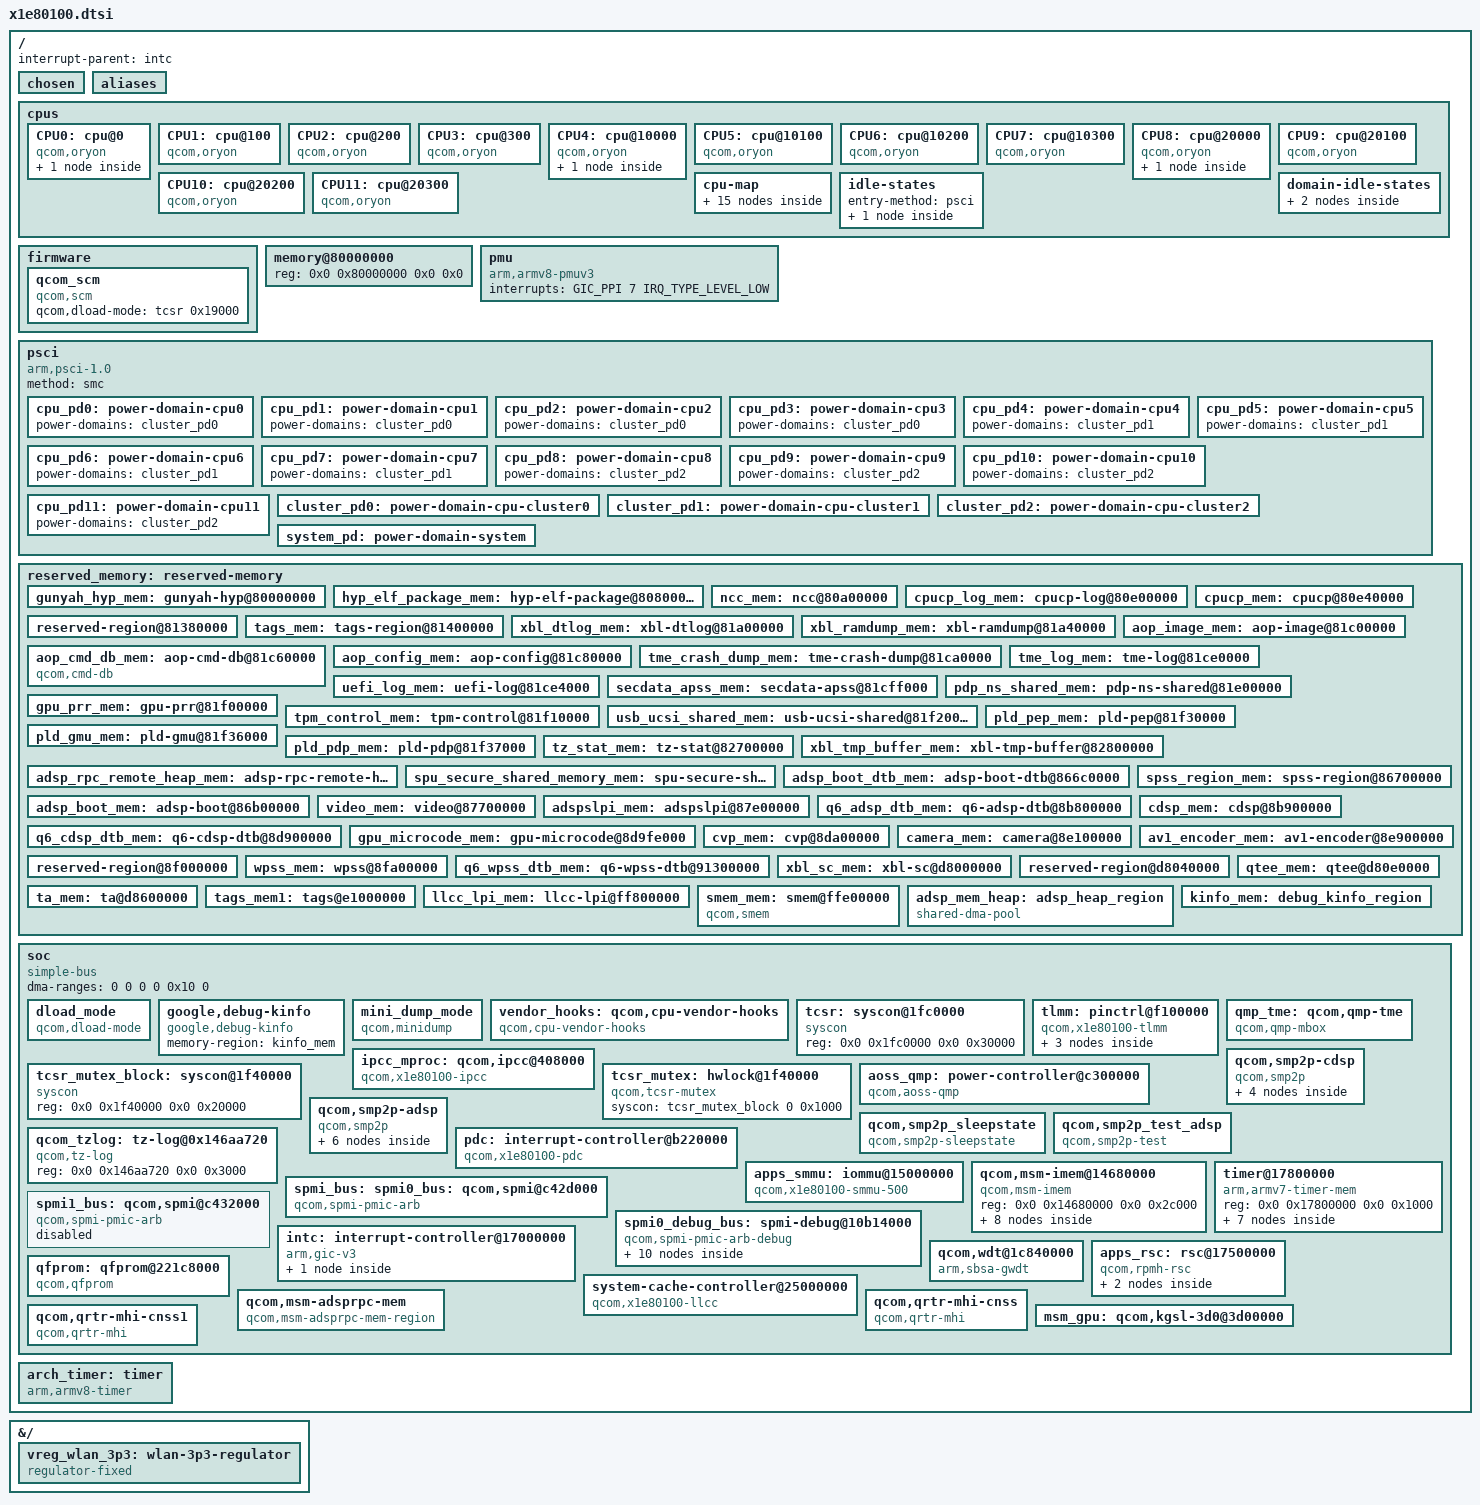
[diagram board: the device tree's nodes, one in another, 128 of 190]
// SPDX-License-Identifier: BSD-3-Clause
/*
 * Copyright (c) Qualcomm Technologies, Inc. and/or its subsidiaries.
 */

#include <dt-bindings/gpio/gpio.h>
#include <dt-bindings/interrupt-controller/arm-gic.h>
#include <dt-bindings/mailbox/qcom-ipcc.h>
#include <dt-bindings/soc/qcom,rpmh-rsc.h>
#include <dt-bindings/spmi/spmi.h>

/ {
	interrupt-parent = <&intc>;

	#address-cells = <2>;
	#size-cells = <2>;

	chosen { };

	aliases { };

	cpus {
		#address-cells = <2>;
		#size-cells = <0>;

		CPU0: cpu@0 {
			device_type = "cpu";
			compatible = "qcom,oryon";
			reg = <0x0 0x0>;
			enable-method = "psci";
			next-level-cache = <&L2_0>;
			power-domains = <&cpu_pd0>;
			power-domain-names = "psci";
			cpu-idle-states = <&cluster_c4>;

			L2_0: l2-cache {
				compatible = "cache";
				cache-level = <2>;
				cache-unified;
			};
		};

		CPU1: cpu@100 {
			device_type = "cpu";
			compatible = "qcom,oryon";
			reg = <0x0 0x100>;
			enable-method = "psci";
			next-level-cache = <&L2_0>;
			power-domains = <&cpu_pd1>;
			power-domain-names = "psci";
			cpu-idle-states = <&cluster_c4>;
		};

		CPU2: cpu@200 {
			device_type = "cpu";
			compatible = "qcom,oryon";
			reg = <0x0 0x200>;
			enable-method = "psci";
			next-level-cache = <&L2_0>;
			power-domains = <&cpu_pd2>;
			power-domain-names = "psci";
			cpu-idle-states = <&cluster_c4>;
		};

		CPU3: cpu@300 {
			device_type = "cpu";
			compatible = "qcom,oryon";
			reg = <0x0 0x300>;
			enable-method = "psci";
			next-level-cache = <&L2_0>;
			power-domains = <&cpu_pd3>;
			power-domain-names = "psci";
			cpu-idle-states = <&cluster_c4>;
		};

		CPU4: cpu@10000 {
			device_type = "cpu";
			compatible = "qcom,oryon";
			reg = <0x0 0x10000>;
			enable-method = "psci";
			next-level-cache = <&L2_1>;
			power-domains = <&cpu_pd4>;
			power-domain-names = "psci";
			cpu-idle-states = <&cluster_c4>;

			L2_1: l2-cache {
				compatible = "cache";
				cache-level = <2>;
				cache-unified;
			};
		};

		CPU5: cpu@10100 {
			device_type = "cpu";
			compatible = "qcom,oryon";
			reg = <0x0 0x10100>;
			enable-method = "psci";
			next-level-cache = <&L2_1>;
			power-domains = <&cpu_pd5>;
			power-domain-names = "psci";
			cpu-idle-states = <&cluster_c4>;
		};

		CPU6: cpu@10200 {
			device_type = "cpu";
			compatible = "qcom,oryon";
			reg = <0x0 0x10200>;
			enable-method = "psci";
			next-level-cache = <&L2_1>;
			power-domains = <&cpu_pd6>;
			power-domain-names = "psci";
			cpu-idle-states = <&cluster_c4>;
		};

		CPU7: cpu@10300 {
			device_type = "cpu";
			compatible = "qcom,oryon";
			reg = <0x0 0x10300>;
			enable-method = "psci";
			next-level-cache = <&L2_1>;
			power-domains = <&cpu_pd7>;
			power-domain-names = "psci";
			cpu-idle-states = <&cluster_c4>;
		};

		CPU8: cpu@20000 {
			device_type = "cpu";
			compatible = "qcom,oryon";
			reg = <0x0 0x20000>;
			enable-method = "psci";
			next-level-cache = <&L2_2>;
			power-domains = <&cpu_pd8>;
			power-domain-names = "psci";
			cpu-idle-states = <&cluster_c4>;

			L2_2: l2-cache {
				compatible = "cache";
				cache-level = <2>;
				cache-unified;
			};
		};

		CPU9: cpu@20100 {
			device_type = "cpu";
			compatible = "qcom,oryon";
			reg = <0x0 0x20100>;
			enable-method = "psci";
			next-level-cache = <&L2_2>;
			power-domains = <&cpu_pd9>;
			power-domain-names = "psci";
			cpu-idle-states = <&cluster_c4>;
		};

		CPU10: cpu@20200 {
			device_type = "cpu";
			compatible = "qcom,oryon";
			reg = <0x0 0x20200>;
			enable-method = "psci";
			next-level-cache = <&L2_2>;
			power-domains = <&cpu_pd10>;
			power-domain-names = "psci";
			cpu-idle-states = <&cluster_c4>;
		};

		CPU11: cpu@20300 {
			device_type = "cpu";
			compatible = "qcom,oryon";
			reg = <0x0 0x20300>;
			enable-method = "psci";
			next-level-cache = <&L2_2>;
			power-domains = <&cpu_pd11>;
			power-domain-names = "psci";
			cpu-idle-states = <&cluster_c4>;
		};

		cpu-map {
			cluster0 {
				core0 {
					cpu = <&CPU0>;
				};

				core1 {
					cpu = <&CPU1>;
				};

				core2 {
					cpu = <&CPU2>;
				};

				core3 {
					cpu = <&CPU3>;
				};
			};

			cluster1 {
				core0 {
					cpu = <&CPU4>;
				};

				core1 {
					cpu = <&CPU5>;
				};

				core2 {
					cpu = <&CPU6>;
				};

				core3 {
					cpu = <&CPU7>;
				};
			};

			cpu_map_cluster2: cluster2 {
				core0 {
					cpu = <&cpu8>;
				};

				core1 {
					cpu = <&cpu9>;
				};

				core2 {
					cpu = <&cpu10>;
				};

				core3 {
					cpu = <&cpu11>;
				};

			};
		};

		idle-states {
			entry-method = "psci";

			cluster_c4: cpu-sleep-0 {
				compatible = "arm,idle-state";
				idle-state-name = "ret";
				arm,psci-suspend-param = <0x00000004>;
				entry-latency-us = <180>;
				exit-latency-us = <500>;
				min-residency-us = <600>;
			};
		};

		domain-idle-states {
			cluster_cl4: cluster-sleep-0 {
				compatible = "domain-idle-state";
				arm,psci-suspend-param = <0x01000044>;
				entry-latency-us = <350>;
				exit-latency-us = <500>;
				min-residency-us = <2500>;
			};

			cluster_cl5: cluster-sleep-1 {
				compatible = "domain-idle-state";
				arm,psci-suspend-param = <0x01000054>;
				entry-latency-us = <2200>;
				exit-latency-us = <4000>;
				min-residency-us = <7000>;
			};
		};
	};

	firmware {
		qcom_scm {
			compatible = "qcom,scm";
			qcom,dload-mode = <&tcsr 0x19000>;
		};
	};

	memory@80000000 {
		device_type = "memory";
		/* We expect the bootloader to fill in the size */
		reg = <0x0 0x80000000 0x0 0x0>;
	};

	pmu {
		compatible = "arm,armv8-pmuv3";
		interrupts = <GIC_PPI 7 IRQ_TYPE_LEVEL_LOW>;
	};

	psci {
		compatible = "arm,psci-1.0";
		method = "smc";

		cpu_pd0: power-domain-cpu0 {
			#power-domain-cells = <0>;
			power-domains = <&cluster_pd0>;
		};

		cpu_pd1: power-domain-cpu1 {
			#power-domain-cells = <0>;
			power-domains = <&cluster_pd0>;
		};

		cpu_pd2: power-domain-cpu2 {
			#power-domain-cells = <0>;
			power-domains = <&cluster_pd0>;
		};

		cpu_pd3: power-domain-cpu3 {
			#power-domain-cells = <0>;
			power-domains = <&cluster_pd0>;
		};

		cpu_pd4: power-domain-cpu4 {
			#power-domain-cells = <0>;
			power-domains = <&cluster_pd1>;
		};

		cpu_pd5: power-domain-cpu5 {
			#power-domain-cells = <0>;
			power-domains = <&cluster_pd1>;
		};

		cpu_pd6: power-domain-cpu6 {
			#power-domain-cells = <0>;
			power-domains = <&cluster_pd1>;
		};

		cpu_pd7: power-domain-cpu7 {
			#power-domain-cells = <0>;
			power-domains = <&cluster_pd1>;
		};

		cpu_pd8: power-domain-cpu8 {
			#power-domain-cells = <0>;
			power-domains = <&cluster_pd2>;
		};

		cpu_pd9: power-domain-cpu9 {
			#power-domain-cells = <0>;
			power-domains = <&cluster_pd2>;
		};

		cpu_pd10: power-domain-cpu10 {
			#power-domain-cells = <0>;
			power-domains = <&cluster_pd2>;
		};

		cpu_pd11: power-domain-cpu11 {
			#power-domain-cells = <0>;
			power-domains = <&cluster_pd2>;
		};

		cluster_pd0: power-domain-cpu-cluster0 {
			#power-domain-cells = <0>;
			domain-idle-states = <&cluster_cl4>, <&cluster_cl5>;
			power-domains = <&system_pd>;
		};

		cluster_pd1: power-domain-cpu-cluster1 {
			#power-domain-cells = <0>;
			domain-idle-states = <&cluster_cl4>, <&cluster_cl5>;
			power-domains = <&system_pd>;
		};

		cluster_pd2: power-domain-cpu-cluster2 {
			#power-domain-cells = <0>;
			domain-idle-states = <&cluster_cl4>, <&cluster_cl5>;
			power-domains = <&system_pd>;
		};

		system_pd: power-domain-system {
			#power-domain-cells = <0>;
			/* TODO: system-wide idle states */
		};
	};

	reserved_memory: reserved-memory {
		#address-cells = <2>;
		#size-cells = <2>;
		ranges;

		gunyah_hyp_mem: gunyah-hyp@80000000 {
			reg = <0x0 0x80000000 0x0 0x800000>;
			no-map;
		};

		hyp_elf_package_mem: hyp-elf-package@80800000 {
			reg = <0x0 0x80800000 0x0 0x200000>;
			no-map;
		};

		ncc_mem: ncc@80a00000 {
			reg = <0x0 0x80a00000 0x0 0x400000>;
			no-map;
		};

		cpucp_log_mem: cpucp-log@80e00000 {
			reg = <0x0 0x80e00000 0x0 0x40000>;
			no-map;
		};

		cpucp_mem: cpucp@80e40000 {
			reg = <0x0 0x80e40000 0x0 0x540000>;
			no-map;
		};

		reserved-region@81380000 {
			reg = <0x0 0x81380000 0x0 0x80000>;
			no-map;
		};

		tags_mem: tags-region@81400000 {
			reg = <0x0 0x81400000 0x0 0x1a0000>;
			no-map;
		};

		xbl_dtlog_mem: xbl-dtlog@81a00000 {
			reg = <0x0 0x81a00000 0x0 0x40000>;
			no-map;
		};

		xbl_ramdump_mem: xbl-ramdump@81a40000 {
			reg = <0x0 0x81a40000 0x0 0x1c0000>;
			no-map;
		};

		aop_image_mem: aop-image@81c00000 {
			reg = <0x0 0x81c00000 0x0 0x60000>;
			no-map;
		};

		aop_cmd_db_mem: aop-cmd-db@81c60000 {
			compatible = "qcom,cmd-db";
			reg = <0x0 0x81c60000 0x0 0x20000>;
			no-map;
		};

		aop_config_mem: aop-config@81c80000 {
			reg = <0x0 0x81c80000 0x0 0x20000>;
			no-map;
		};

		tme_crash_dump_mem: tme-crash-dump@81ca0000 {
			reg = <0x0 0x81ca0000 0x0 0x40000>;
			no-map;
		};

		tme_log_mem: tme-log@81ce0000 {
			reg = <0x0 0x81ce0000 0x0 0x4000>;
			no-map;
		};

		uefi_log_mem: uefi-log@81ce4000 {
			reg = <0x0 0x81ce4000 0x0 0x10000>;
			no-map;
		};

		secdata_apss_mem: secdata-apss@81cff000 {
			reg = <0x0 0x81cff000 0x0 0x1000>;
			no-map;
		};

		pdp_ns_shared_mem: pdp-ns-shared@81e00000 {
			reg = <0x0 0x81e00000 0x0 0x100000>;
			no-map;
		};

		gpu_prr_mem: gpu-prr@81f00000 {
			reg = <0x0 0x81f00000 0x0 0x10000>;
			no-map;
		};

		tpm_control_mem: tpm-control@81f10000 {
			reg = <0x0 0x81f10000 0x0 0x10000>;
			no-map;
		};

		usb_ucsi_shared_mem: usb-ucsi-shared@81f20000 {
			reg = <0x0 0x81f20000 0x0 0x10000>;
			no-map;
		};

		pld_pep_mem: pld-pep@81f30000 {
			reg = <0x0 0x81f30000 0x0 0x6000>;
			no-map;
		};

		pld_gmu_mem: pld-gmu@81f36000 {
			reg = <0x0 0x81f36000 0x0 0x1000>;
			no-map;
		};

		pld_pdp_mem: pld-pdp@81f37000 {
			reg = <0x0 0x81f37000 0x0 0x1000>;
			no-map;
		};

		tz_stat_mem: tz-stat@82700000 {
			reg = <0x0 0x82700000 0x0 0x100000>;
			no-map;
		};

		xbl_tmp_buffer_mem: xbl-tmp-buffer@82800000 {
			reg = <0x0 0x82800000 0x0 0xc00000>;
			no-map;
		};

		adsp_rpc_remote_heap_mem: adsp-rpc-remote-heap@84b00000 {
			reg = <0x0 0x84b00000 0x0 0x800000>;
			no-map;
		};

		spu_secure_shared_memory_mem: spu-secure-shared-memory@85300000 {
			reg = <0x0 0x85300000 0x0 0x80000>;
			no-map;
		};

		adsp_boot_dtb_mem: adsp-boot-dtb@866c0000 {
			reg = <0x0 0x866c0000 0x0 0x40000>;
			no-map;
		};

		spss_region_mem: spss-region@86700000 {
			reg = <0x0 0x86700000 0x0 0x400000>;
			no-map;
		};

		adsp_boot_mem: adsp-boot@86b00000 {
			reg = <0x0 0x86b00000 0x0 0xc00000>;
			no-map;
		};

		video_mem: video@87700000 {
			reg = <0x0 0x87700000 0x0 0x700000>;
			no-map;
		};

		adspslpi_mem: adspslpi@87e00000 {
			reg = <0x0 0x87e00000 0x0 0x3a00000>;
			no-map;
		};

		q6_adsp_dtb_mem: q6-adsp-dtb@8b800000 {
			reg = <0x0 0x8b800000 0x0 0x80000>;
			no-map;
		};

		cdsp_mem: cdsp@8b900000 {
			reg = <0x0 0x8b900000 0x0 0x2000000>;
			no-map;
		};

		q6_cdsp_dtb_mem: q6-cdsp-dtb@8d900000 {
			reg = <0x0 0x8d900000 0x0 0x80000>;
			no-map;
		};

		gpu_microcode_mem: gpu-microcode@8d9fe000 {
			reg = <0x0 0x8d9fe000 0x0 0x2000>;
			no-map;
		};

		cvp_mem: cvp@8da00000 {
			reg = <0x0 0x8da00000 0x0 0x700000>;
			no-map;
		};

		camera_mem: camera@8e100000 {
			reg = <0x0 0x8e100000 0x0 0x800000>;
			no-map;
		};

		av1_encoder_mem: av1-encoder@8e900000 {
			reg = <0x0 0x8e900000 0x0 0x700000>;
			no-map;
		};

		reserved-region@8f000000 {
			reg = <0x0 0x8f000000 0x0 0xa00000>;
			no-map;
		};

		wpss_mem: wpss@8fa00000 {
			reg = <0x0 0x8fa00000 0x0 0x1900000>;
			no-map;
		};

		q6_wpss_dtb_mem: q6-wpss-dtb@91300000 {
			reg = <0x0 0x91300000 0x0 0x80000>;
			no-map;
		};

		xbl_sc_mem: xbl-sc@d8000000 {
			reg = <0x0 0xd8000000 0x0 0x40000>;
			no-map;
		};

		reserved-region@d8040000 {
			reg = <0x0 0xd8040000 0x0 0xa0000>;
			no-map;
		};

		qtee_mem: qtee@d80e0000 {
			reg = <0x0 0xd80e0000 0x0 0x520000>;
			no-map;
		};

		ta_mem: ta@d8600000 {
			reg = <0x0 0xd8600000 0x0 0x8a00000>;
			no-map;
		};

		tags_mem1: tags@e1000000 {
			reg = <0x0 0xe1000000 0x0 0x26a0000>;
			no-map;
		};

		llcc_lpi_mem: llcc-lpi@ff800000 {
			reg = <0x0 0xff800000 0x0 0x600000>;
			no-map;
		};

		smem_mem: smem@ffe00000 {
			compatible = "qcom,smem";
			reg = <0x0 0xffe00000 0x0 0x200000>;
			hwlocks = <&tcsr_mutex 3>;
			no-map;
		};

		adsp_mem_heap: adsp_heap_region {
			compatible = "shared-dma-pool";
			alloc-ranges = <0x0 0x00000000 0x0 0xffffffff>;
			reusable;
			alignment = <0x0 0x400000>;
			size = <0x0 0xC00000>;
		};

		kinfo_mem: debug_kinfo_region {
			alloc-ranges = <0x0 0x00000000 0xffffffff 0xffffffff>;
			size = <0x0 0x1000>;
			no-map;
		};
	};

	soc: soc {
		compatible = "simple-bus";

		#address-cells = <2>;
		#size-cells = <2>;
		dma-ranges = <0 0 0 0 0x10 0>;
		ranges = <0 0 0 0 0x10 0>;

		dload_mode {
			compatible = "qcom,dload-mode";
		};

		google,debug-kinfo {
			compatible = "google,debug-kinfo";
			memory-region = <&kinfo_mem>;
		};

		mini_dump_mode {
			compatible = "qcom,minidump";
			status = "ok";
		};

		vendor_hooks: qcom,cpu-vendor-hooks {
			compatible = "qcom,cpu-vendor-hooks";
		};

		tcsr: syscon@1fc0000 {
			compatible = "syscon";
			reg = <0x0 0x1fc0000 0x0 0x30000>;
		};

		tlmm: pinctrl@f100000 {
			compatible = "qcom,x1e80100-tlmm";
			reg = <0x0 0x0f100000 0x0 0xf00000>;

			interrupts = <GIC_SPI 208 IRQ_TYPE_LEVEL_HIGH>;

			gpio-controller;
			#gpio-cells = <2>;

			interrupt-controller;
			#interrupt-cells = <2>;

			gpio-ranges = <&tlmm 0 0 239>;
			gpio-reserved-ranges = <34 2>, <44 4>, <238 1>;
		};

		ipcc_mproc: qcom,ipcc@408000 {
			compatible = "qcom,x1e80100-ipcc", "qcom,ipcc";
			reg = <0x0 0x00408000 0x0 0x1000>;

			interrupts = <GIC_SPI 229 IRQ_TYPE_LEVEL_HIGH>;
			interrupt-controller;
			#interrupt-cells = <3>;

			#mbox-cells = <2>;
		};

		tcsr_mutex_block: syscon@1f40000 {
			compatible = "syscon";
			reg = <0x0 0x1f40000 0x0 0x20000>;
		};

		tcsr_mutex: hwlock@1f40000 {
			compatible = "qcom,tcsr-mutex";
			syscon = <&tcsr_mutex_block 0 0x1000>;
			#hwlock-cells = <1>;
		};

		aoss_qmp: power-controller@c300000 {
			compatible = "qcom,aoss-qmp";
			reg = <0x0 0xc300000 0x0 0x400>;
			interrupt-parent = <&ipcc_mproc>;
			interrupts = <IPCC_CLIENT_AOP
				      IPCC_MPROC_SIGNAL_GLINK_QMP
				      IRQ_TYPE_EDGE_RISING>;
			mboxes = <&ipcc_mproc IPCC_CLIENT_AOP
				  IPCC_MPROC_SIGNAL_GLINK_QMP>;

			#power-domain-cells = <1>;
			#clock-cells = <0>;
		};

		qmp_tme: qcom,qmp-tme {
			compatible = "qcom,qmp-mbox";
			qcom,remote-pid = <14>;
			mboxes = <&ipcc_mproc IPCC_CLIENT_TME
				  IPCC_MPROC_SIGNAL_GLINK_QMP>;
			mbox-names = "tme_qmp";
			interrupt-parent = <&ipcc_mproc>;
			interrupts = <IPCC_CLIENT_TME
				      IPCC_MPROC_SIGNAL_GLINK_QMP
				      IRQ_TYPE_EDGE_RISING>;

			label = "tme";
			qcom,early-boot;
			priority = <0>;
			mbox-desc-offset = <0x0>;
			#mbox-cells = <1>;
		};

		qcom,smp2p-cdsp {
			compatible = "qcom,smp2p";
			qcom,smem = <94>, <432>;
			interrupt-parent = <&ipcc_mproc>;
			interrupts = <IPCC_CLIENT_CDSP IPCC_MPROC_SIGNAL_SMP2P
				      IRQ_TYPE_EDGE_RISING>;
			mboxes = <&ipcc_mproc IPCC_CLIENT_CDSP IPCC_MPROC_SIGNAL_SMP2P>;
			qcom,local-pid = <0>;
			qcom,remote-pid = <5>;

			cdsp_smp2p_out: master-kernel {
				qcom,entry-name = "master-kernel";
				#qcom,smem-state-cells = <1>;
			};

			cdsp_smp2p_in: slave-kernel {
				qcom,entry-name = "slave-kernel";
				interrupt-controller;
				#interrupt-cells = <2>;
			};

			smp2p_test5_in: qcom,smp2p-test5-in {
				qcom,entry-name = "smp2p";
				interrupt-controller;
				#interrupt-cells = <2>;
			};

			smp2p_test5_out: qcom,smp2p-test5-out {
				qcom,entry-name = "smp2p";
				#qcom,smem-state-cells = <1>;
			};
		};

		qcom,smp2p-adsp {
			compatible = "qcom,smp2p";
			qcom,smem = <443>, <429>;
			interrupt-parent = <&ipcc_mproc>;
			interrupts = <IPCC_CLIENT_LPASS IPCC_MPROC_SIGNAL_SMP2P
				      IRQ_TYPE_EDGE_RISING>;
			mboxes = <&ipcc_mproc IPCC_CLIENT_LPASS
				  IPCC_MPROC_SIGNAL_SMP2P>;
			qcom,local-pid = <0>;
			qcom,remote-pid = <2>;

			adsp_smp2p_out: master-kernel {
				qcom,entry-name = "master-kernel";
				#qcom,smem-state-cells = <1>;
			};

			adsp_smp2p_in: slave-kernel {
				qcom,entry-name = "slave-kernel";
				interrupt-controller;
				#interrupt-cells = <2>;
			};

			sleepstate_smp2p_out: sleepstate-out {
				qcom,entry-name = "sleepstate";
				#qcom,smem-state-cells = <1>;
			};

			sleepstate_smp2p_in: qcom,sleepstate-in {
				qcom,entry-name = "sleepstate_see";
				interrupt-controller;
				#interrupt-cells = <2>;
			};

			smp2p_test2_in: qcom,smp2p-test2-in {
				qcom,entry-name = "smp2p";
				interrupt-controller;
				#interrupt-cells = <2>;
			};

			smp2p_test2_out: qcom,smp2p-test2-out {
				qcom,entry-name = "smp2p";
				#qcom,smem-state-cells = <1>;
			};
		};

		qcom,smp2p_sleepstate {
			compatible = "qcom,smp2p-sleepstate";
			qcom,smem-states = <&sleepstate_smp2p_out 0>;
			interrupt-parent = <&sleepstate_smp2p_in>;
			interrupts = <0 0>;
			interrupt-names = "smp2p-sleepstate-in";
		};

		qcom,smp2p_test_adsp {
			compatible = "qcom,smp2p-test";
			label = "adsp";
			qcom,smem-states = <&smp2p_test2_out 0>;
			interrupts-extended = <&smp2p_test2_in 0 0>;
		};

		pdc: interrupt-controller@b220000 {
			compatible = "qcom,x1e80100-pdc", "qcom,pdc";
			reg = <0x0 0x0b220000 0x0 0x30000>, <0x0 0x174000f0 0x0 0x64>;

			qcom,pdc-ranges = <0 480 42>, <42 251 5>,
					  <47 522 52>, <99 609 32>,
					  <131 717 12>, <143 816 19>;
			#interrupt-cells = <2>;
			interrupt-parent = <&intc>;
			interrupt-controller;
		};

		qcom_tzlog: tz-log@0x146aa720 {
			compatible = "qcom,tz-log";
			reg = <0x0 0x146aa720 0x0 0x3000>;
		};

		apps_smmu: iommu@15000000 {
			compatible = "qcom,x1e80100-smmu-500", "qcom,smmu-500", "arm,mmu-500";
			reg = <0x0 0x15000000 0x0 0x100000>;

			interrupts = <GIC_SPI 65 IRQ_TYPE_LEVEL_HIGH>,
				     <GIC_SPI 97 IRQ_TYPE_LEVEL_HIGH>,
				     <GIC_SPI 98 IRQ_TYPE_LEVEL_HIGH>,
				     <GIC_SPI 99 IRQ_TYPE_LEVEL_HIGH>,
				     <GIC_SPI 100 IRQ_TYPE_LEVEL_HIGH>,
				     <GIC_SPI 101 IRQ_TYPE_LEVEL_HIGH>,
				     <GIC_SPI 102 IRQ_TYPE_LEVEL_HIGH>,
				     <GIC_SPI 103 IRQ_TYPE_LEVEL_HIGH>,
				     <GIC_SPI 104 IRQ_TYPE_LEVEL_HIGH>,
				     <GIC_SPI 105 IRQ_TYPE_LEVEL_HIGH>,
				     <GIC_SPI 106 IRQ_TYPE_LEVEL_HIGH>,
				     <GIC_SPI 107 IRQ_TYPE_LEVEL_HIGH>,
				     <GIC_SPI 108 IRQ_TYPE_LEVEL_HIGH>,
				     <GIC_SPI 109 IRQ_TYPE_LEVEL_HIGH>,
				     <GIC_SPI 110 IRQ_TYPE_LEVEL_HIGH>,
				     <GIC_SPI 111 IRQ_TYPE_LEVEL_HIGH>,
				     <GIC_SPI 112 IRQ_TYPE_LEVEL_HIGH>,
				     <GIC_SPI 113 IRQ_TYPE_LEVEL_HIGH>,
				     <GIC_SPI 114 IRQ_TYPE_LEVEL_HIGH>,
				     <GIC_SPI 115 IRQ_TYPE_LEVEL_HIGH>,
				     <GIC_SPI 116 IRQ_TYPE_LEVEL_HIGH>,
				     <GIC_SPI 117 IRQ_TYPE_LEVEL_HIGH>,
				     <GIC_SPI 118 IRQ_TYPE_LEVEL_HIGH>,
				     <GIC_SPI 181 IRQ_TYPE_LEVEL_HIGH>,
				     <GIC_SPI 182 IRQ_TYPE_LEVEL_HIGH>,
				     <GIC_SPI 183 IRQ_TYPE_LEVEL_HIGH>,
				     <GIC_SPI 184 IRQ_TYPE_LEVEL_HIGH>,
				     <GIC_SPI 185 IRQ_TYPE_LEVEL_HIGH>,
				     <GIC_SPI 186 IRQ_TYPE_LEVEL_HIGH>,
				     <GIC_SPI 187 IRQ_TYPE_LEVEL_HIGH>,
				     <GIC_SPI 188 IRQ_TYPE_LEVEL_HIGH>,
				     <GIC_SPI 189 IRQ_TYPE_LEVEL_HIGH>,
				     <GIC_SPI 190 IRQ_TYPE_LEVEL_HIGH>,
				     <GIC_SPI 191 IRQ_TYPE_LEVEL_HIGH>,
				     <GIC_SPI 192 IRQ_TYPE_LEVEL_HIGH>,
				     <GIC_SPI 315 IRQ_TYPE_LEVEL_HIGH>,
				     <GIC_SPI 316 IRQ_TYPE_LEVEL_HIGH>,
				     <GIC_SPI 317 IRQ_TYPE_LEVEL_HIGH>,
				     <GIC_SPI 318 IRQ_TYPE_LEVEL_HIGH>,
				     <GIC_SPI 319 IRQ_TYPE_LEVEL_HIGH>,
				     <GIC_SPI 320 IRQ_TYPE_LEVEL_HIGH>,
				     <GIC_SPI 321 IRQ_TYPE_LEVEL_HIGH>,
				     <GIC_SPI 322 IRQ_TYPE_LEVEL_HIGH>,
				     <GIC_SPI 323 IRQ_TYPE_LEVEL_HIGH>,
				     <GIC_SPI 324 IRQ_TYPE_LEVEL_HIGH>,
				     <GIC_SPI 325 IRQ_TYPE_LEVEL_HIGH>,
				     <GIC_SPI 326 IRQ_TYPE_LEVEL_HIGH>,
				     <GIC_SPI 327 IRQ_TYPE_LEVEL_HIGH>,
				     <GIC_SPI 328 IRQ_TYPE_LEVEL_HIGH>,
				     <GIC_SPI 329 IRQ_TYPE_LEVEL_HIGH>,
				     <GIC_SPI 330 IRQ_TYPE_LEVEL_HIGH>,
				     <GIC_SPI 331 IRQ_TYPE_LEVEL_HIGH>,
				     <GIC_SPI 332 IRQ_TYPE_LEVEL_HIGH>,
				     <GIC_SPI 333 IRQ_TYPE_LEVEL_HIGH>,
				     <GIC_SPI 334 IRQ_TYPE_LEVEL_HIGH>,
				     <GIC_SPI 335 IRQ_TYPE_LEVEL_HIGH>,
				     <GIC_SPI 336 IRQ_TYPE_LEVEL_HIGH>,
				     <GIC_SPI 337 IRQ_TYPE_LEVEL_HIGH>,
				     <GIC_SPI 338 IRQ_TYPE_LEVEL_HIGH>,
				     <GIC_SPI 339 IRQ_TYPE_LEVEL_HIGH>,
				     <GIC_SPI 340 IRQ_TYPE_LEVEL_HIGH>,
				     <GIC_SPI 341 IRQ_TYPE_LEVEL_HIGH>,
				     <GIC_SPI 342 IRQ_TYPE_LEVEL_HIGH>,
				     <GIC_SPI 343 IRQ_TYPE_LEVEL_HIGH>,
				     <GIC_SPI 344 IRQ_TYPE_LEVEL_HIGH>,
				     <GIC_SPI 345 IRQ_TYPE_LEVEL_HIGH>,
				     <GIC_SPI 395 IRQ_TYPE_LEVEL_HIGH>,
				     <GIC_SPI 396 IRQ_TYPE_LEVEL_HIGH>,
				     <GIC_SPI 397 IRQ_TYPE_LEVEL_HIGH>,
				     <GIC_SPI 398 IRQ_TYPE_LEVEL_HIGH>,
				     <GIC_SPI 399 IRQ_TYPE_LEVEL_HIGH>,
				     <GIC_SPI 400 IRQ_TYPE_LEVEL_HIGH>,
				     <GIC_SPI 401 IRQ_TYPE_LEVEL_HIGH>,
				     <GIC_SPI 402 IRQ_TYPE_LEVEL_HIGH>,
				     <GIC_SPI 403 IRQ_TYPE_LEVEL_HIGH>,
				     <GIC_SPI 404 IRQ_TYPE_LEVEL_HIGH>,
				     <GIC_SPI 405 IRQ_TYPE_LEVEL_HIGH>,
				     <GIC_SPI 406 IRQ_TYPE_LEVEL_HIGH>,
				     <GIC_SPI 407 IRQ_TYPE_LEVEL_HIGH>,
				     <GIC_SPI 408 IRQ_TYPE_LEVEL_HIGH>,
				     <GIC_SPI 409 IRQ_TYPE_LEVEL_HIGH>,
				     <GIC_SPI 418 IRQ_TYPE_LEVEL_HIGH>,
				     <GIC_SPI 419 IRQ_TYPE_LEVEL_HIGH>,
				     <GIC_SPI 412 IRQ_TYPE_LEVEL_HIGH>,
				     <GIC_SPI 421 IRQ_TYPE_LEVEL_HIGH>,
				     <GIC_SPI 707 IRQ_TYPE_LEVEL_HIGH>,
				     <GIC_SPI 423 IRQ_TYPE_LEVEL_HIGH>,
				     <GIC_SPI 424 IRQ_TYPE_LEVEL_HIGH>,
				     <GIC_SPI 425 IRQ_TYPE_LEVEL_HIGH>,
				     <GIC_SPI 690 IRQ_TYPE_LEVEL_HIGH>,
				     <GIC_SPI 691 IRQ_TYPE_LEVEL_HIGH>,
				     <GIC_SPI 692 IRQ_TYPE_LEVEL_HIGH>,
				     <GIC_SPI 693 IRQ_TYPE_LEVEL_HIGH>,
				     <GIC_SPI 694 IRQ_TYPE_LEVEL_HIGH>,
				     <GIC_SPI 695 IRQ_TYPE_LEVEL_HIGH>,
				     <GIC_SPI 696 IRQ_TYPE_LEVEL_HIGH>,
				     <GIC_SPI 697 IRQ_TYPE_LEVEL_HIGH>;

			#iommu-cells = <2>;
			#global-interrupts = <1>;

			dma-coherent;
		};

		qcom,msm-imem@14680000 {
			compatible = "qcom,msm-imem";
			reg = <0x0 0x14680000 0x0 0x2c000>;
			ranges = <0x0 0x0 0x14680000 0x2c000>;
			#address-cells = <1>;
			#size-cells = <1>;

			mem_dump_table@2a010 {
				compatible = "qcom,msm-imem-mem_dump_table";
				reg = <0x2a010 0x8>;
			};

			restart_reason@2a65c {
				compatible = "qcom,msm-imem-restart_reason";
				reg = <0x2a65c 0x4>;
			};

			dload_type@2a01c {
				compatible = "qcom,msm-imem-dload-type";
				reg = <0x2a01c 0x4>;
			};

			boot_stats@2a6b0 {
				compatible = "qcom,msm-imem-boot_stats";
				reg = <0x2a6b0 0x20>;
			};

			kaslr_offset@2a6d0 {
				compatible = "qcom,msm-imem-kaslr_offset";
				reg = <0x2a6d0 0xc>;
			};

			pil@2a94c {
				compatible = "qcom,pil-reloc-info";
				reg = <0x2a94c 0xc8>;
			};

			pil@2a6dc {
				compatible = "qcom,msm-imem-pil-disable-timeout";
				reg = <0x2a6dc 0x4>;
			};

			diag_dload@2a0c8 {
				compatible = "qcom,msm-imem-diag-dload";
				reg = <0x2a0c8 0xc8>;
			};
		};

		spmi_bus: spmi0_bus: qcom,spmi@c42d000 {
			compatible = "qcom,spmi-pmic-arb";
			reg = <0x0 0xc42d000 0x0 0x4000>,
			      <0x0 0xc400000 0x0 0x3000>,
			      <0x0 0xc500000 0x0 0x400000>,
			      <0x0 0xc440000 0x0 0x80000>,
			      <0x0 0xc4c0000 0x0 0x10000>;
			reg-names = "cnfg", "core", "chnls", "obsrvr", "intr";
			interrupts = <GIC_SPI 481 IRQ_TYPE_LEVEL_HIGH>;
			interrupt-names = "periph_irq";
			interrupt-controller;
			#interrupt-cells = <4>;
			#address-cells = <2>;
			#size-cells = <0>;
			cell-index = <0>;
			qcom,channel = <0>;
			qcom,ee = <0>;
			qcom,bus-id = <0>;
		};

		spmi1_bus: qcom,spmi@c432000 {
			compatible = "qcom,spmi-pmic-arb";
			reg = <0x0 0xc432000 0x0 0x4000>,
			      <0x0 0xc400000 0x0 0x3000>,
			      <0x0 0xc500000 0x0 0x400000>,
			      <0x0 0xc440000 0x0 0x80000>,
			      <0x0 0xc4d0000 0x0 0x10000>;
			reg-names = "cnfg", "core", "chnls", "obsrvr", "intr";
			interrupts = <GIC_SPI 483 IRQ_TYPE_LEVEL_HIGH>;
			interrupt-names = "periph_irq";
			interrupt-controller;
			#interrupt-cells = <4>;
			#address-cells = <2>;
			#size-cells = <0>;
			cell-index = <0>;
			qcom,channel = <0>;
			qcom,ee = <0>;
			qcom,bus-id = <1>;
			depends-on-supply = <&spmi0_bus>;
			status = "disabled";
		};

		spmi0_debug_bus: spmi-debug@10b14000 {
			compatible = "qcom,spmi-pmic-arb-debug";
			reg = <0x0 0x10b14000 0x0 0x60>, <0x0 0x221c8784 0x0 0x4>;
			reg-names = "core", "fuse";
			clocks = <&aoss_qmp>;
			clock-names = "core_clk";
			qcom,fuse-enable-bit = <18>;
			#address-cells = <2>;
			#size-cells = <0>;
			depends-on-supply = <&spmi_bus>;

			pmk8550@0 {
				compatible = "qcom,spmi-pmic";
				reg = <0 SPMI_USID>;
				#address-cells = <2>;
				#size-cells = <0>;
				qcom,can-sleep;
			};

			pm8550@1 {
				compatible = "qcom,spmi-pmic";
				reg = <1 SPMI_USID>;
				#address-cells = <2>;
				#size-cells = <0>;
				qcom,can-sleep;
			};

			pm8550ve@2 {
				compatible = "qcom,spmi-pmic";
				reg = <2 SPMI_USID>;
				#address-cells = <2>;
				#size-cells = <0>;
				qcom,can-sleep;
			};

			pmc8380@3 {
				compatible = "qcom,spmi-pmic";
				reg = <3 SPMI_USID>;
				#address-cells = <2>;
				#size-cells = <0>;
				qcom,can-sleep;
			};

			pmc8380@4 {
				compatible = "qcom,spmi-pmic";
				reg = <4 SPMI_USID>;
				#address-cells = <2>;
				#size-cells = <0>;
				qcom,can-sleep;
			};

			pmc8380@5 {
				compatible = "qcom,spmi-pmic";
				reg = <5 SPMI_USID>;
				#address-cells = <2>;
				#size-cells = <0>;
				qcom,can-sleep;
			};

			pmc8380@6 {
				compatible = "qcom,spmi-pmic";
				reg = <6 SPMI_USID>;
				#address-cells = <2>;
				#size-cells = <0>;
				qcom,can-sleep;
			};

			pm8550ve@8 {
				compatible = "qcom,spmi-pmic";
				reg = <8 SPMI_USID>;
				#address-cells = <2>;
				#size-cells = <0>;
				qcom,can-sleep;
			};

			pm8550ve@9 {
				compatible = "qcom,spmi-pmic";
				reg = <9 SPMI_USID>;
				#address-cells = <2>;
				#size-cells = <0>;
				qcom,can-sleep;
			};

			pm8010@c {
				compatible = "qcom,spmi-pmic";
				reg = <12 SPMI_USID>;
				#address-cells = <2>;
				#size-cells = <0>;
				qcom,can-sleep;
			};
		};

		intc: interrupt-controller@17000000 {
			compatible = "arm,gic-v3";
			reg = <0x0 0x17000000 0x0 0x10000>,     /* GICD */
			      <0x0 0x17080000 0x0 0x300000>;    /* GICR * 12 */

			interrupts = <GIC_PPI 9 IRQ_TYPE_LEVEL_HIGH>;

			#interrupt-cells = <3>;
			interrupt-controller;

			#redistributor-regions = <1>;
			redistributor-stride = <0x0 0x40000>;

			#address-cells = <2>;
			#size-cells = <2>;
			ranges;

			gic_its: msi-controller@17040000 {
				compatible = "arm,gic-v3-its";
				reg = <0x0 0x17040000 0x0 0x40000>;

				msi-controller;
				#msi-cells = <1>;

				status = "disabled";
			};
		};

		timer@17800000 {
			compatible = "arm,armv7-timer-mem";
			reg = <0x0 0x17800000 0x0 0x1000>;

			#address-cells = <2>;
			#size-cells = <1>;
			ranges = <0x0 0x0 0x0 0x0 0x20000000>;

			frame@17801000 {
				reg = <0x0 0x17801000 0x1000>,
				      <0x0 0x17802000 0x1000>;

				interrupts = <GIC_SPI 8 IRQ_TYPE_LEVEL_HIGH>,
					     <GIC_SPI 6 IRQ_TYPE_LEVEL_HIGH>;

				frame-number = <0>;
			};

			frame@17803000 {
				reg = <0x0 0x17803000 0x1000>;

				interrupts = <GIC_SPI 9 IRQ_TYPE_LEVEL_HIGH>;

				frame-number = <1>;

				status = "disabled";
			};

			frame@17805000 {
				reg = <0x0 0x17805000 0x1000>;

				interrupts = <GIC_SPI 10 IRQ_TYPE_LEVEL_HIGH>;

				frame-number = <2>;

				status = "disabled";
			};

			frame@17807000 {
				reg = <0x0 0x17807000 0x1000>;

				interrupts = <GIC_SPI 11 IRQ_TYPE_LEVEL_HIGH>;

				frame-number = <3>;

				status = "disabled";
			};

			frame@17809000 {
				reg = <0x0 0x17809000 0x1000>;

				interrupts = <GIC_SPI 12 IRQ_TYPE_LEVEL_HIGH>;

				frame-number = <4>;

				status = "disabled";
			};

			frame@1780b000 {
				reg = <0x0 0x1780b000 0x1000>;

				interrupts = <GIC_SPI 13 IRQ_TYPE_LEVEL_HIGH>;

				frame-number = <5>;

				status = "disabled";
			};

			frame@1780d000 {
				reg = <0x0 0x1780d000 0x1000>;

				interrupts = <GIC_SPI 14 IRQ_TYPE_LEVEL_HIGH>;

				frame-number = <6>;

				status = "disabled";
			};
		};

		qcom,wdt@1c840000 {
			compatible = "arm,sbsa-gwdt";
			reg = <0x0 0x1c840000 0x0 0x1000>,
			      <0x0 0x1c850000 0x0 0x1000>;
			interrupts = <GIC_SPI 0 IRQ_TYPE_LEVEL_HIGH>;
		};

		apps_rsc: rsc@17500000 {
			label = "apps_rsc";
			compatible = "qcom,rpmh-rsc";
			reg = <0x0 0x17500000 0x0 0x10000>,
			      <0x0 0x17510000 0x0 0x10000>,
			      <0x0 0x17520000 0x0 0x10000>;
			reg-names = "drv-0", "drv-1", "drv-2";
			qcom,drv-count = <3>;
			interrupts = <GIC_SPI 3 IRQ_TYPE_LEVEL_HIGH>,
				     <GIC_SPI 4 IRQ_TYPE_LEVEL_HIGH>,
				     <GIC_SPI 5 IRQ_TYPE_LEVEL_HIGH>;

			apps_rsc_drv2: drv@2 {
				qcom,drv-id = <2>;
				qcom,tcs-offset = <0xd00>;
				qcom,tcs-distance = <0x2a0>;
				channel@0 {
					qcom,tcs-config = <ACTIVE_TCS    2>,
							  <SLEEP_TCS     3>,
							  <WAKE_TCS      3>,
							  <CONTROL_TCS   0>,
							  <FAST_PATH_TCS 0>;
				};
			};
		};

		qfprom: qfprom@221c8000 {
			compatible = "qcom,qfprom";
			reg = <0x0 0x221c8000 0x0 0x1000>;
			#address-cells = <1>;
			#size-cells = <1>;
			read-only;
			ranges;
		};

		system-cache-controller@25000000 {
			compatible = "qcom,x1e80100-llcc";
			reg = <0x0 0x25000000 0x0 0x200000>,
			      <0x0 0x25200000 0x0 0x200000>,
			      <0x0 0x25400000 0x0 0x200000>,
			      <0x0 0x25600000 0x0 0x200000>,
			      <0x0 0x25800000 0x0 0x200000>,
			      <0x0 0x25a00000 0x0 0x200000>,
			      <0x0 0x25c00000 0x0 0x200000>,
			      <0x0 0x25e00000 0x0 0x200000>,
			      <0x0 0x26000000 0x0 0x200000>,
			      <0x0 0x26200000 0x0 0x200000>;
			reg-names = "llcc0_base",
				    "llcc1_base",
				    "llcc2_base",
				    "llcc3_base",
				    "llcc4_base",
				    "llcc5_base",
				    "llcc6_base",
				    "llcc7_base",
				    "llcc_broadcast_base",
				    "llcc_broadcast_and_base";
			interrupts = <GIC_SPI 266 IRQ_TYPE_LEVEL_HIGH>;
		};

		qcom,msm-adsprpc-mem {
			compatible = "qcom,msm-adsprpc-mem-region";
			memory-region = <&adsp_mem_heap>;
			restrict-access;
		};

		qcom,qrtr-mhi-cnss {
			compatible = "qcom,qrtr-mhi";
			qcom,dev-id = <0x1103>;
			qcom,net-id = <0>;
			qcom,low-latency;
		};

		qcom,qrtr-mhi-cnss1 {
			compatible = "qcom,qrtr-mhi";
			qcom,dev-id = <0x1107>;
			qcom,net-id = <0>;
			qcom,low-latency;
		};

		msm_gpu: qcom,kgsl-3d0@3d00000 { };
	};

	arch_timer: timer {
		compatible = "arm,armv8-timer";

		interrupts = <GIC_PPI 13 IRQ_TYPE_LEVEL_LOW>,
			     <GIC_PPI 14 IRQ_TYPE_LEVEL_LOW>,
			     <GIC_PPI 11 IRQ_TYPE_LEVEL_LOW>,
			     <GIC_PPI 10 IRQ_TYPE_LEVEL_LOW>;
	};
};

&tlmm {
	wlan_tps_3v3_enable_state: wlan-tps-3v3-enable {
		mux {
			pins = "gpio214";
			function = "gpio";
		};

		config {
			pins = "gpio214";
			bias-pull-up;
			output-high;
		};
	};
};

&{/} {
	vreg_wlan_3p3: wlan-3p3-regulator {
		compatible = "regulator-fixed";
		regulator-name = "vreg_wlan_3p3";

		regulator-min-microvolt = <3300000>;
		regulator-max-microvolt = <3300000>;

		gpio = <&tlmm 214 GPIO_ACTIVE_HIGH>;
		enable-active-high;

		pinctrl-names = "default";
		pinctrl-0 = <&wlan_tps_3v3_enable_state>;
	};
};
